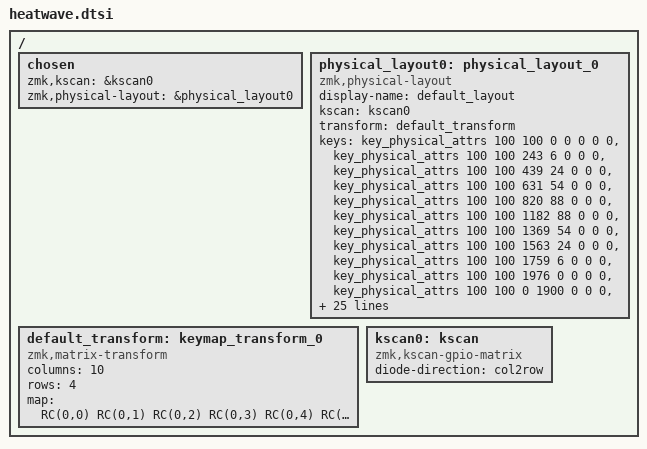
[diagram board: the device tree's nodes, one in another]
#include <dt-bindings/zmk/matrix_transform.h>
#include <physical_layouts.dtsi>

/ {
    chosen {
        zmk,kscan = &kscan0;
        zmk,physical-layout = &physical_layout0;
    }; 

        physical_layout0: physical_layout_0 {
        compatible = "zmk,physical-layout";
        display-name = "default_layout";
        kscan = <&kscan0>;
        transform = <&default_transform>;

        keys  //                     w   h    x    y     rot    rx    ry
            = <&key_physical_attrs 100 100    0    0       0     0     0>
            , <&key_physical_attrs 100 100  243    6       0     0     0>
            , <&key_physical_attrs 100 100  439   24       0     0     0>
            , <&key_physical_attrs 100 100  631   54       0     0     0>
            , <&key_physical_attrs 100 100  820   88       0     0     0>
            , <&key_physical_attrs 100 100 1182   88       0     0     0>
            , <&key_physical_attrs 100 100 1369   54       0     0     0>
            , <&key_physical_attrs 100 100 1563   24       0     0     0>
            , <&key_physical_attrs 100 100 1759    6       0     0     0>
            , <&key_physical_attrs 100 100 1976    0       0     0     0>
            , <&key_physical_attrs 100 100    0 1900       0     0     0>
            , <&key_physical_attrs 100 100  243 1906       0     0     0>
            , <&key_physical_attrs 100 100  439 1924       0     0     0>
            , <&key_physical_attrs 100 100  631 1954       0     0     0>
            , <&key_physical_attrs 100 100  820 1988       0     0     0>
            , <&key_physical_attrs 100 100 1182 1988       0     0     0>
            , <&key_physical_attrs 100 100 1369 1954       0     0     0>
            , <&key_physical_attrs 100 100 1563 1924       0     0     0>
            , <&key_physical_attrs 100 100 1759 1906       0     0     0>
            , <&key_physical_attrs 100 100 1976 1900       0     0     0>
            , <&key_physical_attrs 100 100    0 3800       0     0     0>
            , <&key_physical_attrs 100 100  193 3803       0     0     0>
            , <&key_physical_attrs 100 100  390 3817       0     0     0>
            , <&key_physical_attrs 100 100  585 3850       0     0     0>
            , <&key_physical_attrs 100 100  773 3896       0     0     0>
            , <&key_physical_attrs 100 100 1229 3896       0     0     0>
            , <&key_physical_attrs 100 100 1417 3850       0     0     0>
            , <&key_physical_attrs 100 100 1612 3817       0     0     0>
            , <&key_physical_attrs 100 100 1809 3803       0     0     0>
            , <&key_physical_attrs 100 100 2001 3800       0     0     0>
            , <&key_physical_attrs 100 100  351 6091       0     0     0>
            , <&key_physical_attrs 100 100  580 6515       0     0     0>
            , <&key_physical_attrs 100 100  791 6905       0     0     0>
            , <&key_physical_attrs 100 100 1209 6905       0     0     0>
            , <&key_physical_attrs 100 100 1420 6515       0     0     0>
            , <&key_physical_attrs 100 100 1648 6091       0     0     0>
            ;
    };


    default_transform: keymap_transform_0 {
        compatible = "zmk,matrix-transform";
        columns = <10>;
        rows = <4>;
        map = <
        RC(0,0) RC(0,1) RC(0,2) RC(0,3) RC(0,4)    RC(0,5) RC(0,6) RC(0,7) RC(0,8) RC(0,9)
        RC(1,0) RC(1,1) RC(1,2) RC(1,3) RC(1,4)    RC(1,5) RC(1,6) RC(1,7) RC(1,8) RC(1,9)
        RC(2,0) RC(2,1) RC(2,2) RC(2,3) RC(2,4)    RC(2,5) RC(2,6) RC(2,7) RC(2,8) RC(2,9)
                        RC(3,2) RC(3,3) RC(3,4)    RC(3,5) RC(3,6) RC(3,7)
        >;
    };

    kscan0: kscan {
        compatible = "zmk,kscan-gpio-matrix";
        diode-direction = "col2row";
    };

};
